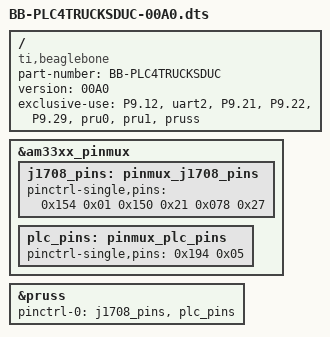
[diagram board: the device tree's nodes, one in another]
/* PLC4TRUCKSDuck (c) 2020 National Motor Freight Traffic Association
* 
* Permission is hereby granted, free of charge, to any person obtaining a copy
* of this software and associated documentation files (the "Software"), to deal
* in the Software without restriction, including without limitation the rights
* to use, copy, modify, merge, publish, distribute, sublicense, and/or sell
* copies of the Software, and to permit persons to whom the Software is
* furnished to do so, subject to the following conditions:
* 
* The above copyright notice and this permission notice shall be included in all
* copies or substantial portions of the Software.
* 
* THE SOFTWARE IS PROVIDED "AS IS", WITHOUT WARRANTY OF ANY KIND, EXPRESS OR
* IMPLIED, INCLUDING BUT NOT LIMITED TO THE WARRANTIES OF MERCHANTABILITY,
* FITNESS FOR A PARTICULAR PURPOSE AND NONINFRINGEMENT. IN NO EVENT SHALL THE
* AUTHORS OR COPYRIGHT HOLDERS BE LIABLE FOR ANY CLAIM, DAMAGES OR OTHER
* LIABILITY, WHETHER IN AN ACTION OF CONTRACT, TORT OR OTHERWISE, ARISING FROM,
* OUT OF OR IN CONNECTION WITH THE SOFTWARE OR THE USE OR OTHER DEALINGS IN THE
* SOFTWARE.)
*/

/dts-v1/;
/plugin/;

/ {
  compatible = "ti,beaglebone", "ti,beaglebone-black";
  part-number = "BB-PLC4TRUCKSDUC"; /* 16 byte name limit */
  version = "00A0";

  exclusive-use =
    "P9.12", /* J1708 GPIO Monitor */
    "uart2", "P9.21", "P9.22", /* UART2 for J1708 */
    "P9.29", /* PLC chirp synth */
    "pru0", "pru1", "pruss";

  fragment@0 {
    target = <&am33xx_pinmux>;
    __overlay__ {
      j1708_pins: pinmux_j1708_pins {
        pinctrl-single,pins = <
          0x154 0x01  /* uart2_txd : MODE1 */
          0x150 0x21  /* uart2_rxd : MODE1|RX_ACTIVE */
          0x078 0x27  /* gpio1[28] : MODE7|RX_ACTIVE */
        >;
      };
    };
  };

  fragment@1 {
    target = <&am33xx_pinmux>;
    __overlay__ {
      plc_pins: pinmux_plc_pins {
        pinctrl-single,pins = <
          0x194 0x05  /* pr1_pru0_pru_r30_1 : MODE5 */
        >;
      };
    };
  };

  fragment@2 {
    target = <&pruss>;
    __overlay__ {
      status = "okay";
      pinctrl-names = "default";
      pinctrl-0 = <&j1708_pins &plc_pins>;
    };
  };
};
